# STM32F302CBT6 register map
File version: 1.0
Registers are 32-bit, access not given, reset 0x0 unless marked. A register's access mark holds for its fields unless they carry their own. Offsets are from the block's base; [hi:lo] are bit positions; {n}, {i} and the like mark numbered series.

## PWR
Base 0x40007000
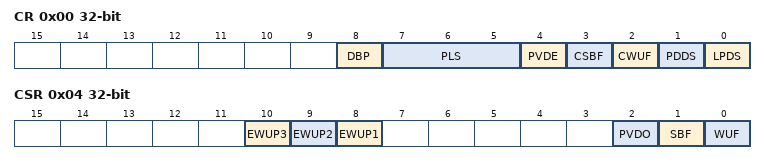
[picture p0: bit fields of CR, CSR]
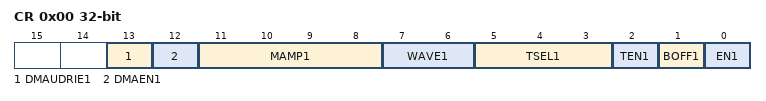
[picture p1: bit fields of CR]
0x00 CR
  [8] DBP, [7:5] PLS, [4] PVDE, [3] CSBF, [2] CWUF, [1] PDDS, [0] LPDS
0x04 CSR
  [10] EWUP3, [9] EWUP2, [8] EWUP1, [2] PVDO, [1] SBF, [0] WUF

## DAC1
Base 0x40007400
0x00 CR
  [13] DMAUDRIE1, [12] DMAEN1, [11:8] MAMP1, [7:6] WAVE1, [5:3] TSEL1, [2] TEN1, [1] BOFF1, [0] EN1
0x04 SWTRIGR
  [0] SWTRIG1
0x08 DHR12R1
  [11:0] DACC1DHR
0x0C DHR12L1
  [15:4] DACC1DHR
0x10 DHR8R1
  [7:0] DACC1DHR
0x2C DOR1
  [11:0] DACC1DOR
0x34 SR
  [13] DMAUDR1

## COMP
Base 0x40010000
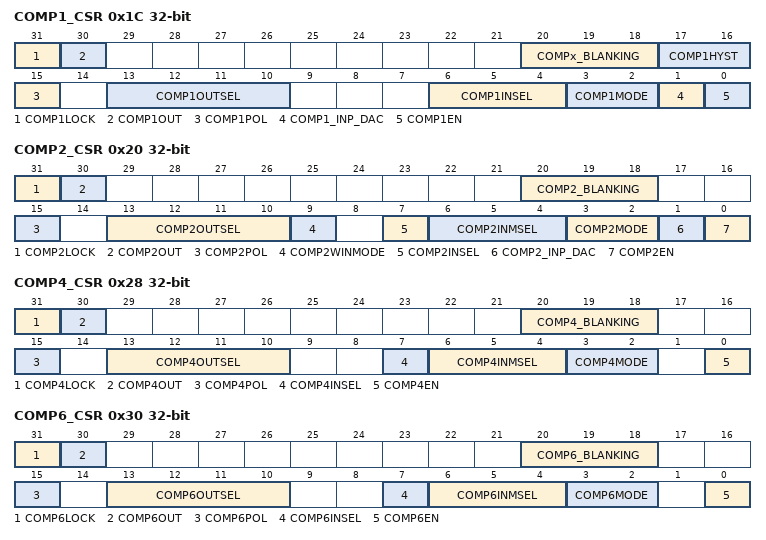
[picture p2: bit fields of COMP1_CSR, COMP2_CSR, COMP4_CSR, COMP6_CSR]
0x1C COMP1_CSR
  [31] COMP1LOCK, [30] COMP1OUT, [20:18] COMPx_BLANKING, [17:16] COMP1HYST, [15] COMP1POL, [13:10] COMP1OUTSEL, [6:4] COMP1INSEL, [3:2] COMP1MODE, [1] COMP1_INP_DAC, [0] COMP1EN
0x20 COMP2_CSR
  [31] COMP2LOCK, [30] COMP2OUT, [20:18] COMP2_BLANKING, [15] COMP2POL, [13:10] COMP2OUTSEL, [9] COMP2WINMODE, [7] COMP2INSEL, [6:4] COMP2INMSEL, [3:2] COMP2MODE, [1] COMP2_INP_DAC, [0] COMP2EN
0x28 COMP4_CSR
  [31] COMP4LOCK, [30] COMP4OUT, [20:18] COMP4_BLANKING, [15] COMP4POL, [13:10] COMP4OUTSEL, [7] COMP4INSEL, [6:4] COMP4INMSEL, [3:2] COMP4MODE, [0] COMP4EN
0x30 COMP6_CSR
  [31] COMP6LOCK, [30] COMP6OUT, [20:18] COMP6_BLANKING, [15] COMP6POL, [13:10] COMP6OUTSEL, [7] COMP6INSEL, [6:4] COMP6INMSEL, [3:2] COMP6MODE, [0] COMP6EN

## SYSCFG
Base 0x40010000
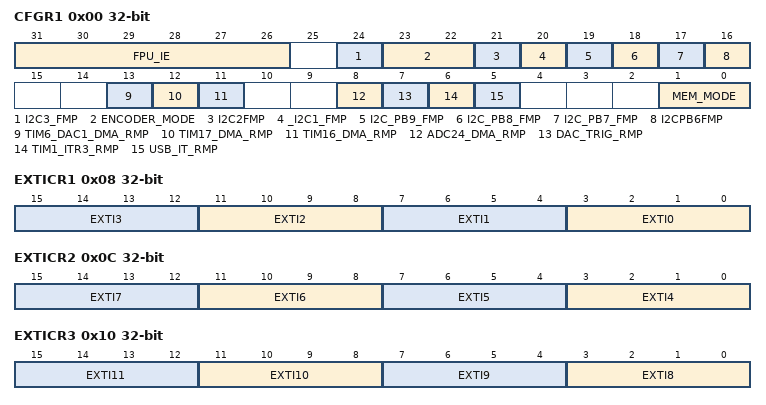
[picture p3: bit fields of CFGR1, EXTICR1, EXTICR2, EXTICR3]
0x00 CFGR1
  [31:26] FPU_IE, [24] I2C3_FMP, [23:22] ENCODER_MODE, [21] I2C2FMP, [20] _I2C1_FMP, [19] I2C_PB9_FMP, [18] I2C_PB8_FMP, [17] I2C_PB7_FMP, [16] I2CPB6FMP, [13] TIM6_DAC1_DMA_RMP, [12] TIM17_DMA_RMP, [11] TIM16_DMA_RMP, [8] ADC24_DMA_RMP, [7] DAC_TRIG_RMP, [6] TIM1_ITR3_RMP, [5] USB_IT_RMP, [1:0] MEM_MODE
0x08 EXTICR1
  [4n+3:4n] EXTI{n} (n=0..3)
0x0C EXTICR2
  [4n-13:4n-16] EXTI{n} (n=4..7)
0x10 EXTICR3
  [4n-29:4n-32] EXTI{n} (n=8..11)
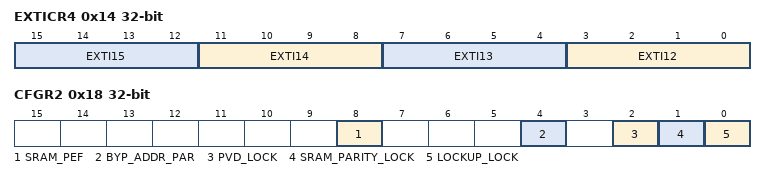
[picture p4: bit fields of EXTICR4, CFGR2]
0x14 EXTICR4
  [4n-45:4n-48] EXTI{n} (n=12..15)
0x18 CFGR2
  [8] SRAM_PEF, [4] BYP_ADDR_PAR, [2] PVD_LOCK, [1] SRAM_PARITY_LOCK, [0] LOCKUP_LOCK

## OPAMP
Base 0x40010000
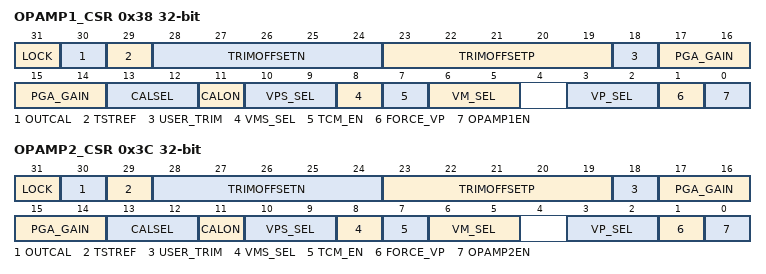
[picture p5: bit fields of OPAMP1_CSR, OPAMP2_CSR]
0x38 OPAMP1_CSR
  [31] LOCK, [30] OUTCAL, [29] TSTREF, [28:24] TRIMOFFSETN, [23:19] TRIMOFFSETP, [18] USER_TRIM, [17:14] PGA_GAIN, [13:12] CALSEL, [11] CALON, [10:9] VPS_SEL, [8] VMS_SEL, [7] TCM_EN, [6:5] VM_SEL, [3:2] VP_SEL, [1] FORCE_VP, [0] OPAMP1EN
0x3C OPAMP2_CSR
  [31] LOCK, [30] OUTCAL, [29] TSTREF, [28:24] TRIMOFFSETN, [23:19] TRIMOFFSETP, [18] USER_TRIM, [17:14] PGA_GAIN, [13:12] CALSEL, [11] CALON, [10:9] VPS_SEL, [8] VMS_SEL, [7] TCM_EN, [6:5] VM_SEL, [3:2] VP_SEL, [1] FORCE_VP, [0] OPAMP2EN

## EXTI
Base 0x40010400
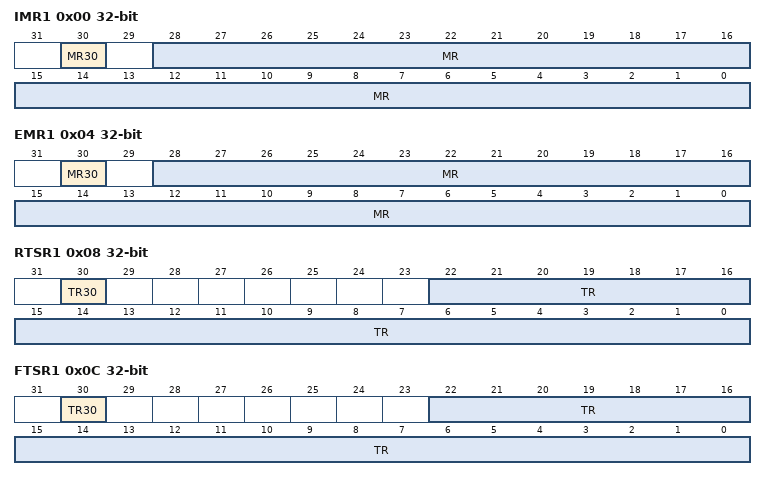
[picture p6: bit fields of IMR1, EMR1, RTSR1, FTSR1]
0x00 IMR1
  [30] MR30, [28:0] MR
0x04 EMR1
  [30] MR30, [28:0] MR
0x08 RTSR1
  [30] TR30, [22:0] TR
0x0C FTSR1
  [30] TR30, [22:0] TR
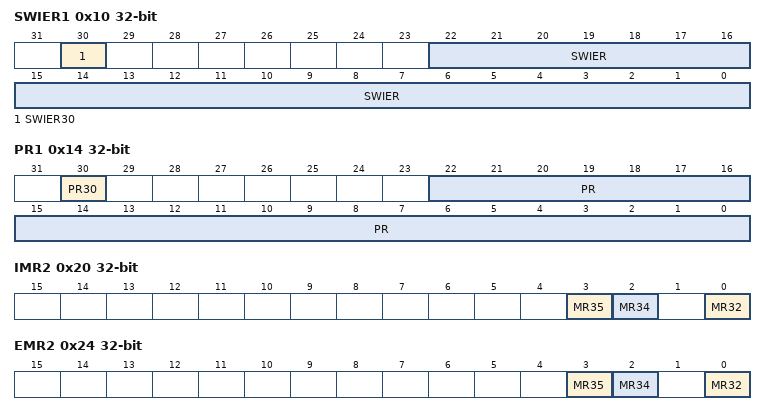
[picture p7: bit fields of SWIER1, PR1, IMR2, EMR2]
0x10 SWIER1
  [30] SWIER30, [22:0] SWIER
0x14 PR1
  [30] PR30, [22:0] PR
0x20 IMR2
  [3] MR35, [2] MR34, [0] MR32
0x24 EMR2
  [3] MR35, [2] MR34, [0] MR32
0x28 RTSR2
  [0] TR32
0x2C FTSR2
  [0] TR32
0x30 SWIER2
  [0] SWIER32
0x34 PR2
  [0] PR32

## TIM1
Base 0x40012C00
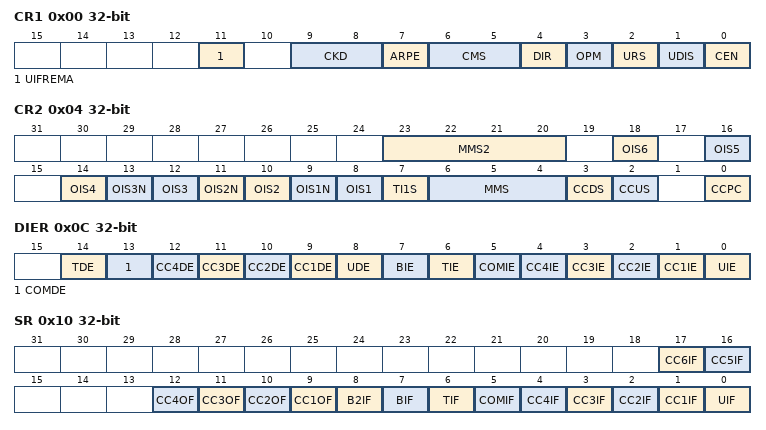
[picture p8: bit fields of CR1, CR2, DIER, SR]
0x00 CR1
  [11] UIFREMA, [9:8] CKD, [7] ARPE, [6:5] CMS, [4] DIR, [3] OPM, [2] URS, [1] UDIS, [0] CEN
0x04 CR2
  [23:20] MMS2, [2n+6] OIS{n} (n=1..6), [13] OIS3N, [11] OIS2N, [9] OIS1N, [7] TI1S, [6:4] MMS, [3] CCDS, [2] CCUS, [0] CCPC
0x08 SMCR
  [15] ETP, [14] ECE, [13:12] ETPS, [11:8] ETF, [7] MSM, [6:4] TS, [3] OCCS, [16:0] SMS
0x0C DIER
  [14] TDE, [13] COMDE, [n+8] CC{n}DE (n=1..4), [8] UDE, [7] BIE, [6] TIE, [5] COMIE, [n] CC{n}IE (n=1..4), [0] UIE
0x10 SR
  [17] CC6IF, [16] CC5IF, [n+8] CC{n}OF (n=1..4), [8] B2IF, [7] BIF, [6] TIF, [5] COMIF, [n] CC{n}IF (n=1..4), [0] UIF
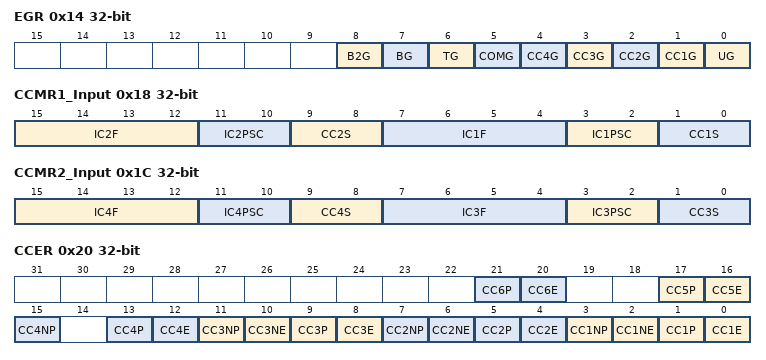
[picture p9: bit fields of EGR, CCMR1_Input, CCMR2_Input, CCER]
0x14 EGR
  [8] B2G, [7] BG, [6] TG, [5] COMG, [n] CC{n}G (n=1..4), [0] UG
0x18 CCMR1_Input
  [15:12] IC2F, [11:10] IC2PSC, [9:8] CC2S, [7:4] IC1F, [3:2] IC1PSC, [1:0] CC1S
0x18 CCMR1_Output
  [15] OC2CE, [24:12] OC2M, [11] OC2PE, [10] OC2FE, [9:8] CC2S, [7] OC1CE, [16:4] OC1M, [3] OC1PE, [2] OC1FE, [1:0] CC1S
0x1C CCMR2_Input
  [15:12] IC4F, [11:10] IC4PSC, [9:8] CC4S, [7:4] IC3F, [3:2] IC3PSC, [1:0] CC3S
0x1C CCMR2_Output
  [15] OC4CE, [24:12] OC4M, [11] OC4PE, [10] OC4FE, [9:8] CC4S, [7] OC3CE, [16:4] OC3M, [3] OC3PE, [2] OC3FE, [1:0] CC3S
0x20 CCER
  [4n-3] CC{n}P (n=1..6), [4n-4] CC{n}E (n=1..6), [4n-1] CC{n}NP (n=1..4), [10] CC3NE, [6] CC2NE, [2] CC1NE
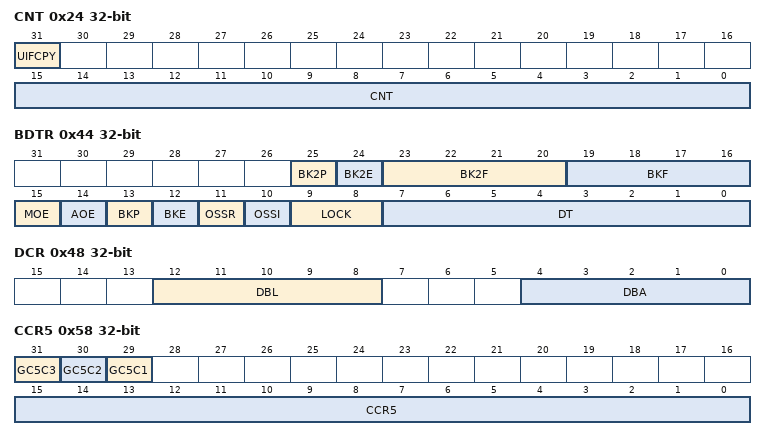
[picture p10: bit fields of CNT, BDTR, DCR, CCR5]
0x24 CNT
  [31] UIFCPY, [15:0] CNT
0x28 PSC
  [15:0] PSC
0x2C ARR
  [15:0] ARR
0x30 RCR
  [15:0] REP
{0x30+4i} CCR{i} (i=1..4)
  [15:0] CCR{i}
0x44 BDTR
  [25] BK2P, [24] BK2E, [23:20] BK2F, [19:16] BKF, [15] MOE, [14] AOE, [13] BKP, [12] BKE, [11] OSSR, [10] OSSI, [9:8] LOCK, [7:0] DT
0x48 DCR
  [12:8] DBL, [4:0] DBA
0x4C DMAR
  [31:0] DMAB
0x50 OR
  [1:0] TIM1_ETR_ADC1_RMP
0x54 CCMR3_Output
  [15] OC6CE, [24:12] OC6M, [11] OC6PE, [10] OC6FE, [7] OC5CE, [16:4] OC5M, [3] OC5PE, [2] OC5FE
0x58 CCR5
  [31] GC5C3, [30] GC5C2, [29] GC5C1, [15:0] CCR5
0x5C CCR6
  [15:0] CCR6
